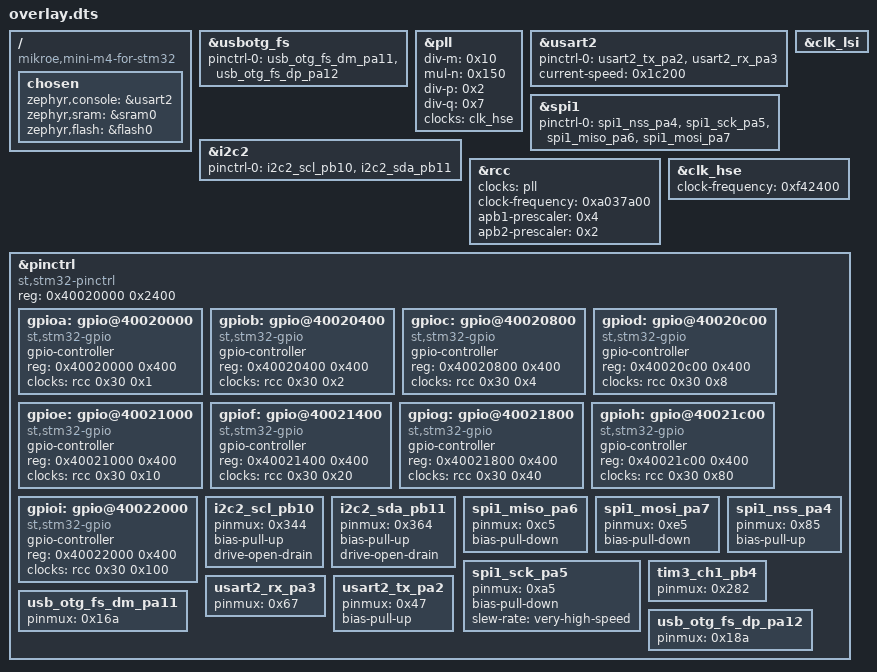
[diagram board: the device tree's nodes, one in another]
/ {
	compatible = "mikroe,mini-m4-for-stm32";
	chosen {
		zephyr,console = &usart2;
		zephyr,sram = &sram0;
		zephyr,flash = &flash0;
	};
};
&usbotg_fs{
	status = "okay";
	pinctrl-0 = < &usb_otg_fs_dm_pa11 &usb_otg_fs_dp_pa12 >;
	pinctrl-names = "default";
};
&pll{
	status = "okay";
	div-m = < 0x10 >;
	mul-n = < 0x150 >;
	div-p = < 0x2 >;
	div-q = < 0x7 >;
	clocks = < &clk_hse >;
};
&usart2{
	status = "okay";
	pinctrl-0 = < &usart2_tx_pa2 &usart2_rx_pa3 >;
	pinctrl-names = "default";
	current-speed = < 0x1c200 >;
};
&spi1{
	status = "okay";
	pinctrl-0 = < &spi1_nss_pa4 &spi1_sck_pa5 &spi1_miso_pa6 &spi1_mosi_pa7 >;
	pinctrl-names = "default";
};
&clk_lsi{
	status = "okay";
};
&i2c2{
	status = "okay";
	pinctrl-0 = < &i2c2_scl_pb10 &i2c2_sda_pb11 >;
	pinctrl-names = "default";
};
&rcc{
	clocks = < &pll >;
	clock-frequency = < 0xa037a00 >;
	apb1-prescaler = < 0x4 >;
	apb2-prescaler = < 0x2 >;
};
&clk_hse{
	status = "okay";
	clock-frequency = < 0xf42400 >;
};
&pinctrl{
	compatible = "st,stm32-pinctrl";
	#address-cells = < 0x1 >;
	#size-cells = < 0x1 >;
	reg = < 0x40020000 0x2400 >;
	gpioa: gpio@40020000 {
		compatible = "st,stm32-gpio";
		gpio-controller;
		#gpio-cells = < 0x2 >;
		reg = < 0x40020000 0x400 >;
		clocks = < &rcc 0x30 0x1 >;
	};
	gpiob: gpio@40020400 {
		compatible = "st,stm32-gpio";
		gpio-controller;
		#gpio-cells = < 0x2 >;
		reg = < 0x40020400 0x400 >;
		clocks = < &rcc 0x30 0x2 >;
	};
	gpioc: gpio@40020800 {
		compatible = "st,stm32-gpio";
		gpio-controller;
		#gpio-cells = < 0x2 >;
		reg = < 0x40020800 0x400 >;
		clocks = < &rcc 0x30 0x4 >;
	};
	gpiod: gpio@40020c00 {
		compatible = "st,stm32-gpio";
		gpio-controller;
		#gpio-cells = < 0x2 >;
		reg = < 0x40020c00 0x400 >;
		clocks = < &rcc 0x30 0x8 >;
	};
	gpioe: gpio@40021000 {
		compatible = "st,stm32-gpio";
		gpio-controller;
		#gpio-cells = < 0x2 >;
		reg = < 0x40021000 0x400 >;
		clocks = < &rcc 0x30 0x10 >;
	};
	gpiof: gpio@40021400 {
		compatible = "st,stm32-gpio";
		gpio-controller;
		#gpio-cells = < 0x2 >;
		reg = < 0x40021400 0x400 >;
		clocks = < &rcc 0x30 0x20 >;
	};
	gpiog: gpio@40021800 {
		compatible = "st,stm32-gpio";
		gpio-controller;
		#gpio-cells = < 0x2 >;
		reg = < 0x40021800 0x400 >;
		clocks = < &rcc 0x30 0x40 >;
	};
	gpioh: gpio@40021c00 {
		compatible = "st,stm32-gpio";
		gpio-controller;
		#gpio-cells = < 0x2 >;
		reg = < 0x40021c00 0x400 >;
		clocks = < &rcc 0x30 0x80 >;
	};
	gpioi: gpio@40022000 {
		compatible = "st,stm32-gpio";
		gpio-controller;
		#gpio-cells = < 0x2 >;
		reg = < 0x40022000 0x400 >;
		clocks = < &rcc 0x30 0x100 >;
	};
	i2c2_scl_pb10: i2c2_scl_pb10 {
		pinmux = < 0x344 >;
		bias-pull-up;
		drive-open-drain;
	};
	i2c2_sda_pb11: i2c2_sda_pb11 {
		pinmux = < 0x364 >;
		bias-pull-up;
		drive-open-drain;
	};
	spi1_miso_pa6: spi1_miso_pa6 {
		pinmux = < 0xc5 >;
		bias-pull-down;
	};
	spi1_mosi_pa7: spi1_mosi_pa7 {
		pinmux = < 0xe5 >;
		bias-pull-down;
	};
	spi1_nss_pa4: spi1_nss_pa4 {
		pinmux = < 0x85 >;
		bias-pull-up;
	};
	spi1_sck_pa5: spi1_sck_pa5 {
		pinmux = < 0xa5 >;
		bias-pull-down;
		slew-rate = "very-high-speed";
	};
	tim3_ch1_pb4: tim3_ch1_pb4 {
		pinmux = < 0x282 >;
	};
	usart2_rx_pa3: usart2_rx_pa3 {
		pinmux = < 0x67 >;
	};
	usart2_tx_pa2: usart2_tx_pa2 {
		pinmux = < 0x47 >;
		bias-pull-up;
	};
	usb_otg_fs_dm_pa11: usb_otg_fs_dm_pa11 {
		pinmux = < 0x16a >;
	};
	usb_otg_fs_dp_pa12: usb_otg_fs_dp_pa12 {
		pinmux = < 0x18a >;
	};
};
